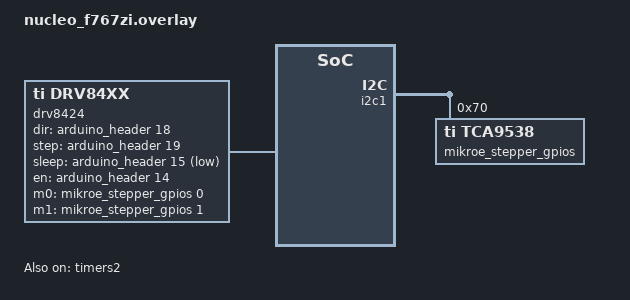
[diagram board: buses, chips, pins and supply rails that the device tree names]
/*
 * Copyright (c) 2024 Navimatix GmbH
 * SPDX-License-Identifier: Apache-2.0
 */

#include <zephyr/dt-bindings/gpio/gpio.h>

/ {
	aliases {
		stepper =  &drv8424;
	};
};

&i2c1 {
	status = "okay";

	mikroe_stepper_gpios: mikroe_stepper_ctrl_tca9538a@70 {
		status = "okay";
		compatible = "ti,tca9538";

		reg = <0x70>;

		gpio-controller;
		ngpios = <8>;
		#gpio-cells = <2>;

		gpio-reserved-ranges = <7 1>;

		gpio-line-names =
			"M0",
			"M1",
			"DEC0",
			"DEC1",
			"TOFF",
			"STP",
			"DIR";
	};
};

/ {
	 drv8424: drv8424 {
		status = "okay";
		compatible = "ti,drv84xx";

		dir-gpios = <&arduino_header 18 0>; /* D12 */
		step-gpios = <&arduino_header 19 0>; /* D13 */
		sleep-gpios = <&arduino_header 15 GPIO_ACTIVE_LOW>; /* D9 */
		en-gpios  = <&arduino_header 14 0>; /* D8 */
		m0-gpios = <&mikroe_stepper_gpios 0 0>;
		m1-gpios = <&mikroe_stepper_gpios 1 0>;
		counter = <&counter2>;

		#address-cells = <1>;
		#size-cells = <0>;
		#stepper-motor-cells = <0>;
	};
};

&timers2 {
	status = "okay";
	counter2: counter {
		status = "okay";
	};
};
